# apollo3 register map
Vendor: Ambiq Micro; Series: Apollo; File version: 1.0
CPU: CM4 r1p0, little endian, MPU, FPU, 3 interrupt priority bits
Registers are 32-bit, read-write, reset 0x0 unless marked. A register's access mark holds for its fields unless they carry their own. Offsets are from the block's base; [hi:lo] are bit positions; 'fields as' and 'values as' point back to an identical list.

## CLKGEN — Clock Generator
Base 0x40004000
0x00 CALXT — XT Oscillator Control
  [10:0] CALXT — XT Oscillator calibration value. This register will enable the hardware to increase or decrease the number of cycles in a 16KHz clock derived from the original 32KHz version. The most significant bit is the sign. A '1' is a reduction, and a '0' is an addition. This calibration value will add or reduce the number of cycles programmed here across a 32 second interval. The maximum value that is effective is from -1024 to 1023.
0x04 CALRC — RC Oscillator Control
  [17:0] CALRC — LFRC Oscillator calibration value. This register will enable the hardware to increase or decrease the number of cycles in a 512 Hz clock derived from the original 1024 version. The most significant bit is the sign. A '1' is a reduction, and a '0' is an addition. This calibration value will add or reduce the number of cycles programmed here across a 32 second interval. The range is from -131072 (decimal) to 131071 (decimal). This register is normally used in conjuction with ACALCTR register. The CALRC register will load the ACALCTR register (bits 17:0) if the ACALCTR register is set to measure the LFRC with the XT clock.
0x08 ACALCTR — Autocalibration Counter
  [23:0] ACALCTR — Autocalibration Counter result. Bits 17 down to 0 of this is feed directly to the CALRC register if ACAL register in OCTRL register is set to 1024SEC or 512SEC.
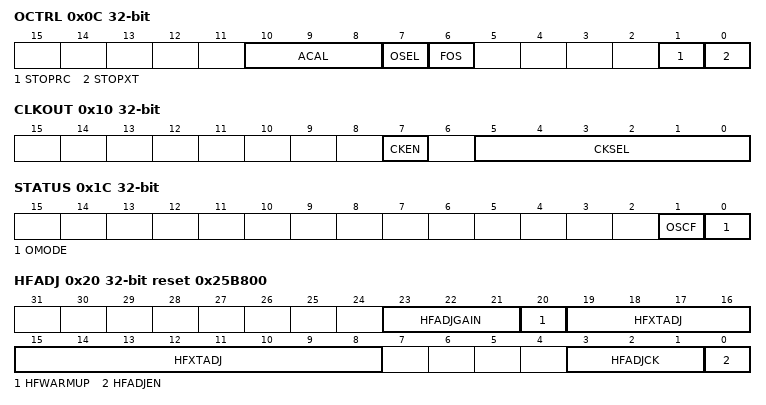
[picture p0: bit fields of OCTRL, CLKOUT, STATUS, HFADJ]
0x0C OCTRL — Oscillator Control
  [10:8] ACAL — Autocalibration control. This selects the source to be used in the autocalibration flow. This flow can also be used to measure an internal clock against an external clock source, with the external clock normally used as the reference.
    0=DIS (Disable Autocalibration value.); 2=1024SEC (Autocalibrate every 1024 seconds. Once autocalibration is done, an interrupt will be triggered at the end of 1024 seconds. value.); 3=512SEC (Autocalibrate every 512 seconds. Once autocalibration is done, an interrupt will be trigged at the end of 512 seconds. value.); 6=XTFREQ (Frequency measurement using XT. The XT clock is normally considered much more accurate than the LFRC clock source. value.); 7=EXTFREQ (Frequency measurement using external clock. value.)
  [7] OSEL — Selects the RTC oscillator (1 => LFRC, 0 => XT)
    0=RTC_XT (RTC uses the XT value.); 1=RTC_LFRC (RTC uses the LFRC value.)
  [6] FOS — Oscillator switch on failure function. If this is set, then LFRC clock source will switch from XT to RC.
    0=DIS (Disable the oscillator switch on failure function. value.); 1=EN (Enable the oscillator switch on failure function. value.)
  [1] STOPRC — Stop the LFRC Oscillator to the RTC
    0=EN (Enable the LFRC Oscillator to drive the RTC value.); 1=STOP (Stop the LFRC Oscillator when driving the RTC value.)
  [0] STOPXT — Stop the XT Oscillator to the RTC
    0=EN (Enable the XT Oscillator to drive the RTC value.); 1=STOP (Stop the XT Oscillator when driving the RTC value.)
0x10 CLKOUT — CLKOUT Frequency Select
  [7] CKEN — Enable the CLKOUT signal
    0=DIS (Disable CLKOUT value.); 1=EN (Enable CLKOUT value.)
  [5:0] CKSEL — CLKOUT signal select
    0=LFRC (LFRC value.); 1=XT_DIV2 (XT / 2 value.); 2=XT_DIV4 (XT / 4 value.); 3=XT_DIV8 (XT / 8 value.); 4=XT_DIV16 (XT / 16 value.); 5=XT_DIV32 (XT / 32 value.); 16=RTC_1Hz (1 Hz as selected in RTC value.); 22=XT_DIV2M (XT / 2^21 value.); 23=XT (XT value.); 24=CG_100Hz (100 Hz as selected in CLKGEN value.); 25=HFRC (HFRC value.); 26=HFRC_DIV4 (HFRC / 4 value.); 27=HFRC_DIV8 (HFRC / 8 value.); 28=HFRC_DIV16 (HFRC / 16 value.); 29=HFRC_DIV64 (HFRC / 64 value.); 30=HFRC_DIV128 (HFRC / 128 value.); 31=HFRC_DIV256 (HFRC / 256 value.); 32=HFRC_DIV512 (HFRC / 512 value.); 34=FLASH_CLK (Flash Clock value.); 35=LFRC_DIV2 (LFRC / 2 value.); 36=LFRC_DIV32 (LFRC / 32 value.); 37=LFRC_DIV512 (LFRC / 512 value.); 38=LFRC_DIV32K (LFRC / 32768 value.); 39=XT_DIV256 (XT / 256 value.); 40=XT_DIV8K (XT / 8192 value.); 41=XT_DIV64K (XT / 2^16 value.); 42=ULFRC_DIV16 (Uncal LFRC / 16 value.); 43=ULFRC_DIV128 (Uncal LFRC / 128 value.); 44=ULFRC_1Hz (Uncal LFRC / 1024 value.); 45=ULFRC_DIV4K (Uncal LFRC / 4096 value.); 46=ULFRC_DIV1M (Uncal LFRC / 2^20 value.); 47=HFRC_DIV64K (HFRC / 2^16 value.); 48=HFRC_DIV16M (HFRC / 2^24 value.); 49=LFRC_DIV1M (LFRC / 2^20 value.); 50=HFRCNE (HFRC (not autoenabled) value.); 51=HFRCNE_DIV8 (HFRC / 8 (not autoenabled) value.); 53=XTNE (XT (not autoenabled) value.); 54=XTNE_DIV16 (XT / 16 (not autoenabled) value.); 55=LFRCNE_DIV32 (LFRC / 32 (not autoenabled) value.); 57=LFRCNE (LFRC (not autoenabled) - Default for undefined values value.)
0x14 CLKKEY — Key Register for Clock Control Register
  [31:0] CLKKEY — Key register value.
    71=Key (Key value.)
0x18 CCTRL reset 0x1 — HFRC Clock Control
  [0] CORESEL — Core Clock divisor
    0=HFRC (Core Clock is HFRC value.); 1=HFRC_DIV2 (Core Clock is HFRC / 2 value.)
0x1C STATUS — Clock Generator Status
  [1] OSCF — XT Oscillator is enabled but not oscillating
  [0] OMODE — Current RTC oscillator (1 => LFRC, 0 => XT). After an RTC oscillator change, it may take up to 2 seconds for this field to reflect the new oscillator.
0x20 HFADJ reset 0x25B800 — HFRC Adjustment
  [23:21] HFADJGAIN — Gain control for HFRC adjustment
    0=Gain_of_1 (HF Adjust with Gain of 1 value.); 1=Gain_of_1_in_2 (HF Adjust with Gain of 0.5 value.); 2=Gain_of_1_in_4 (HF Adjust with Gain of 0.25 value.); 3=Gain_of_1_in_8 (HF Adjust with Gain of 0.125 value.); 4=Gain_of_1_in_16 (HF Adjust with Gain of 0.0625 value.); 5=Gain_of_1_in_32 (HF Adjust with Gain of 0.03125 value.)
  [20] HFWARMUP — XT warmup period for HFRC adjustment
    0=1SEC (Autoadjust XT warmup period = 1-2 seconds value.); 1=2SEC (Autoadjust XT warmup period = 2-4 seconds value.)
  [19:8] HFXTADJ — Target HFRC adjustment value.
  [3:1] HFADJCK — Repeat period for HFRC adjustment
    0=4SEC (Autoadjust repeat period = 4 seconds value.); 1=16SEC (Autoadjust repeat period = 16 seconds value.); 2=32SEC (Autoadjust repeat period = 32 seconds value.); 3=64SEC (Autoadjust repeat period = 64 seconds value.); 4=128SEC (Autoadjust repeat period = 128 seconds value.); 5=256SEC (Autoadjust repeat period = 256 seconds value.); 6=512SEC (Autoadjust repeat period = 512 seconds value.); 7=1024SEC (Autoadjust repeat period = 1024 seconds value.)
  [0] HFADJEN — HFRC adjustment control
    0=DIS (Disable the HFRC adjustment value.); 1=EN (Enable the HFRC adjustment value.)
0x28 CLOCKENSTAT — Clock Enable Status
  [31:0] CLOCKENSTAT — Clock enable status
    1=ADC_CLKEN (Clock enable for the ADC. value.); 2=APBDMA_ACTIVITY_CLKEN (Clock enable for the APBDMA ACTIVITY value.); 4=APBDMA_AOH_CLKEN (Clock enable for the APBDMA AOH DOMAIN value.); 8=APBDMA_AOL_CLKEN (Clock enable for the APBDMA AOL DOMAIN value.); 16=APBDMA_APB_CLKEN (Clock enable for the APBDMA_APB value.); 32=APBDMA_BLEL_CLKEN (Clock enable for the APBDMA_BLEL value.); 64=APBDMA_HCPA_CLKEN (Clock enable for the APBDMA_HCPA value.); 128=APBDMA_HCPB_CLKEN (Clock enable for the APBDMA_HCPB value.); 0x100=APBDMA_HCPC_CLKEN (Clock enable for the APBDMA_HCPC value.); 0x200=APBDMA_MSPI_CLKEN (Clock enable for the APBDMA_MSPI value.); 0x400=APBDMA_PDM_CLKEN (Clock enable for the APBDMA_PDM value.); 0x800=BLEIF_CLK_CLKEN (Clock enable for the BLEIF value.); 0x1000=BLEIF_CLK32K_CLKEN (Clock enable for the BLEIF 32khZ CLOCK value.); 0x2000=CTIMER_CLKEN (Clock enable for the CTIMER BLOCK value.); 0x4000=CTIMER0A_CLKEN (Clock enable for the CTIMER0A value.); 0x8000=CTIMER0B_CLKEN (Clock enable for the CTIMER0B value.); 0x10000=CTIMER1A_CLKEN (Clock enable for the CTIMER1A value.); 0x20000=CTIMER1B_CLKEN (Clock enable for the CTIMER1B value.); 0x40000=CTIMER2A_CLKEN (Clock enable for the CTIMER2A value.); 0x80000=CTIMER2B_CLKEN (Clock enable for the CTIMER2B value.); 0x100000=CTIMER3A_CLKEN (Clock enable for the CTIMER3A value.); 0x200000=CTIMER3B_CLKEN (Clock enable for the CTIMER3B value.); 0x400000=CTIMER4A_CLKEN (Clock enable for the CTIMER4A value.); 0x800000=CTIMER4B_CLKEN (Clock enable for the CTIMER4B value.); 0x1000000=CTIMER5A_CLKEN (Clock enable for the CTIMER5A value.); 0x2000000=CTIMER5B_CLKEN (Clock enable for the CTIMER5B value.); 0x4000000=CTIMER6A_CLKEN (Clock enable for the CTIMER6A value.); 0x8000000=CTIMER6B_CLKEN (Clock enable for the CTIMER6B value.); 0x10000000=CTIMER7A_CLKEN (Clock enable for the CTIMER7A value.); 0x20000000=CTIMER7B_CLKEN (Clock enable for the CTIMER7B value.); 0x40000000=DAP_CLKEN (Clock enable for the DAP value.); 0x80000000=IOMSTRIFC0_CLKEN (Clock enable for the IOMSTRIFC0 value.)
0x2C CLOCKEN2STAT — Clock Enable Status
  [31:0] CLOCKEN2STAT — Clock enable status 2
    1=IOMSTRIFC1_CLKEN (Clock enable for the IO MASTER 1 IFC INTERFACE value.); 2=IOMSTRIFC2_CLKEN (Clock enable for the IO MASTER 2 IFC INTERFACE value.); 4=IOMSTRIFC3_CLKEN (Clock enable for the IO MASTER 3 IFC INTERFACE value.); 8=IOMSTRIFC4_CLKEN (Clock enable for the IO MASTER 4 IFC INTERFACE value.); 16=IOMSTRIFC5_CLKEN (Clock enable for the IO MASTER 5 IFC INTERFACE value.); 32=PDM_CLKEN (Clock enable for the PDM value.); 64=PDMIFC_CLKEN (Clock enable for the PDM INTERFACE value.); 128=PWRCTRL_CLKEN (Clock enable for the PWRCTRL value.); 0x100=RSTGEN_CLKEN (Clock enable for the RSTGEN value.); 0x200=SCARD_CLKEN (Clock enable for the SCARD value.); 0x400=SCARD_ALTAPB_CLKEN (Clock enable for the SCARD ALTAPB value.); 0x800=STIMER_CNT_CLKEN (Clock enable for the STIMER_CNT_CLKEN value.); 0x1000=TPIU_CLKEN (Clock enable for the TPIU_CLKEN value.); 0x2000=UART0HF_CLKEN (Clock enable for the UART0 HF value.); 0x4000=UART1HF_CLKEN (Clock enable for the UART1 HF value.); 0x40000000=XT_32KHZ_EN (Clock enable for the XT 32KHZ value.); 0x80000000=FORCEHFRC (HFRC is forced on Status. value.)
0x30 CLOCKEN3STAT — Clock Enable Status
  [31:0] CLOCKEN3STAT — Clock enable status 3
    0x1000000=XTAL_enabled (XTAL is enabled value.); 0x2000000=HFRC_enabled (HFRC is enabled value.); 0x4000000=HFADJEN (HFRC Adjust enabled value.); 0x8000000=HFRC_en_out (HFRC Enabled out value.); 0x10000000=RTC_XT (RTC use XT value.); 0x20000000=clkout_xtal_en (XTAL clkout enabled value.); 0x40000000=clkout_hfrc_en (HFRC clkout enabled value.); 0x80000000=flashclk_en (Flash clk is enabled value.)
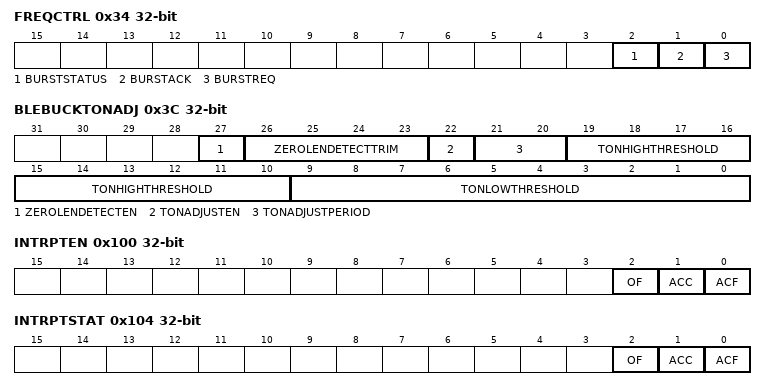
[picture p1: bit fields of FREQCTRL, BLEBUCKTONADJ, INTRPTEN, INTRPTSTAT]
0x34 FREQCTRL — HFRC Frequency Control register
  [2] BURSTSTATUS — This represents frequency burst status.
  [1] BURSTACK — Frequency Burst Request Acknowledge. Frequency burst requested is always acknowledged whether burst is granted or not depending on feature enable.
  [0] BURSTREQ — Frequency Burst Enable Request
    0=DIS (Frequency for ARM core stays at 48MHz value.); 1=EN (Frequency for ARM core is increased to 96MHz value.)
0x3C BLEBUCKTONADJ — BLE BUCK TON ADJUST
  [27] ZEROLENDETECTEN — BLEBUCK ZERO LENGTH DETECT ENABLE
    0=DIS (Disable Zero Length Detect value.); 1=EN (Enable Zero Length Detect value.)
  [26:23] ZEROLENDETECTTRIM — BLEBUCK ZERO LENGTH DETECT TRIM
    15=SetF (Indicator send when the BLE BUCK asserts blebuck_comp1 for about 81us (10 percent margin of error) or more value.); 14=SetE (Indicator send when the BLE BUCK asserts blebuck_comp1 for about 75.6us (10 percent margin of error) or more value.); 13=SetD (Indicator send when the BLE BUCK asserts blebuck_comp1 for about 70.2us (10 percent margin of error) or more value.); 12=SetC (Indicator send when the BLE BUCK asserts blebuck_comp1 for about 64.8us (10 percent margin of error) or more value.); 11=SetB (Indicator send when the BLE BUCK asserts blebuck_comp1 for about 59.4us (10 percent margin of error) or more value.); 10=SetA (Indicator send when the BLE BUCK asserts blebuck_comp1 for about 54.0us (10 percent margin of error) or more value.); 9=Set9 (Indicator send when the BLE BUCK asserts blebuck_comp1 for about 48.6us (10 percent margin of error) or more value.); 8=Set8 (Indicator send when the BLE BUCK asserts blebuck_comp1 for about 43.2us (10 percent margin of error) or more value.); 7=Set7 (Indicator send when the BLE BUCK asserts blebuck_comp1 for about 37.8us (10 percent margin of error) or more value.); 6=Set6 (Indicator send when the BLE BUCK asserts blebuck_comp1 for about 32.4us (10 percent margin of error) or more value.); 5=Set5 (Indicator send when the BLE BUCK asserts blebuck_comp1 for about 27.0us (10 percent margin of error) or more value.); 4=Set4 (Indicator send when the BLE BUCK asserts blebuck_comp1 for about 21.6us (10 percent margin of error) or more value.); 3=Set3 (Indicator send when the BLE BUCK asserts blebuck_comp1 for about 16.2us (10 percent margin of error) or more value.); 2=Set2 (Indicator send when the BLE BUCK asserts blebuck_comp1 for about 10.8us (10 percent margin of error) or more value.); 1=Set1 (Indicator send when the BLE BUCK asserts blebuck_comp1 for about 5.4us (10 percent margin of error) or more value.); 0=Set0 (Indicator send when the BLE BUCK asserts blebuck_comp1 for about 2.0us (10 percent margin of error) or more value.)
  [22] TONADJUSTEN — TON ADJUST ENABLE
    0=DIS (Disable Adjust for BLE BUCK TON trim value.); 1=EN (Enable Adjust for BLE BUCK TON trim value.)
  [21:20] TONADJUSTPERIOD
    3=HFRC_3KHz (Adjust done for every 1 3KHz period value.); 2=HFRC_12KHz (Adjust done for every 1 12KHz period value.); 1=HFRC_47KHz (Adjust done for every 1 47KHz period value.); 0=HFRC_94KHz (Adjust done for every 1 94KHz period value.)
  [19:10] TONHIGHTHRESHOLD — TON ADJUST HIGH THRESHOLD. Suggested values are #15(94KHz) #2A(47Khz) #A6(12Khz) #29A(3Khz)
  [9:0] TONLOWTHRESHOLD — TON ADJUST LOW THRESHOLD. Suggested values are #A(94KHz) #15(47KHz) #53(12Khz) #14D(3Khz)
0x100 INTRPTEN — CLKGEN Interrupt Register: Enable
  [2] OF — XT Oscillator Fail interrupt
  [1] ACC — Autocalibration Complete interrupt
  [0] ACF — Autocalibration Fail interrupt
0x104 INTRPTSTAT — CLKGEN Interrupt Register: Status
  fields as INTRPTEN
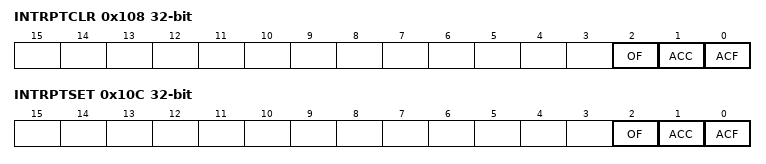
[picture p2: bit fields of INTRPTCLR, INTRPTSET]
0x108 INTRPTCLR — CLKGEN Interrupt Register: Clear
  fields as INTRPTEN
0x10C INTRPTSET — CLKGEN Interrupt Register: Set
  fields as INTRPTEN
